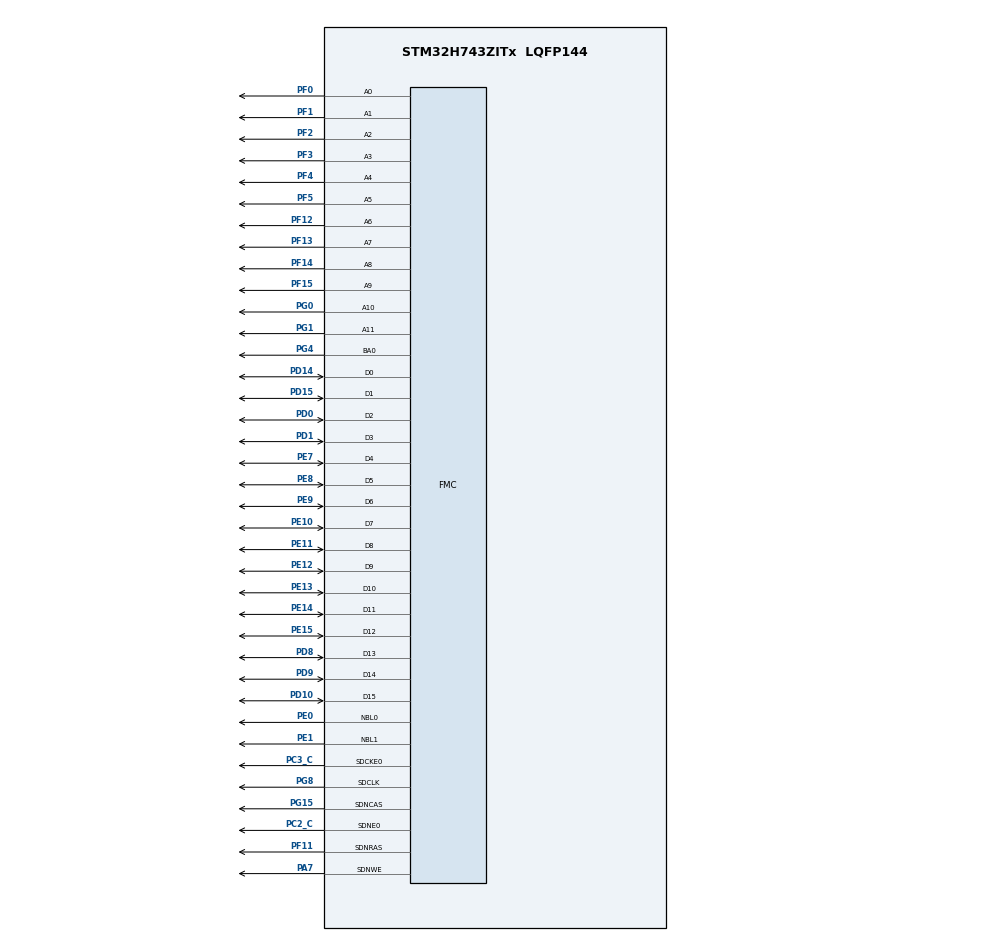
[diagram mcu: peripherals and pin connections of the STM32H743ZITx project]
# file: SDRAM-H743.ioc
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FMC.CASLatency1=FMC_SDRAM_CAS_LATENCY_2
FMC.ExitSelfRefreshDelay1=7
FMC.LoadToActiveDelay1=2
FMC.RCDDelay1=2
FMC.RPDelay1=2
FMC.ReadBurst1=FMC_SDRAM_RBURST_ENABLE
FMC.ReadPipeDelay1=FMC_SDRAM_RPIPE_DELAY_2
FMC.RowCycleDelay1=6
FMC.SDClockPeriod1=FMC_SDRAM_CLOCK_PERIOD_2
FMC.SelfRefreshTime1=6
FMC.WriteRecoveryTime1=4
Mcu.Family=STM32H7
Mcu.Name=STM32H743ZITx
Mcu.Package=LQFP144
NVIC.PriorityGroup=NVIC_PRIORITYGROUP_4
PA7.Signal=FMC_SDNWE
PC2_C.Mode=SdramChipSelect1_1
PC2_C.Signal=FMC_SDNE0
PC3_C.Mode=SdramChipSelect1_1
PC3_C.Signal=FMC_SDCKE0
PD0.Signal=FMC_D2_DA2
PD1.Signal=FMC_D3_DA3
PD10.Signal=FMC_D15_DA15
PD14.Signal=FMC_D0_DA0
PD15.Signal=FMC_D1_DA1
PD8.Signal=FMC_D13_DA13
PD9.Signal=FMC_D14_DA14
PE0.Signal=FMC_NBL0
PE1.Signal=FMC_NBL1
PE10.Signal=FMC_D7_DA7
PE11.Signal=FMC_D8_DA8
PE12.Signal=FMC_D9_DA9
PE13.Signal=FMC_D10_DA10
PE14.Signal=FMC_D11_DA11
PE15.Signal=FMC_D12_DA12
PE7.Signal=FMC_D4_DA4
PE8.Signal=FMC_D5_DA5
PE9.Signal=FMC_D6_DA6
PF0.Signal=FMC_A0
PF1.Signal=FMC_A1
PF11.Signal=FMC_SDNRAS
PF12.Signal=FMC_A6
PF13.Signal=FMC_A7
PF14.Signal=FMC_A8
PF15.Signal=FMC_A9
PF2.Signal=FMC_A2
PF3.Signal=FMC_A3
PF4.Signal=FMC_A4
PF5.Signal=FMC_A5
PG0.Signal=FMC_A10
PG1.Signal=FMC_A11
PG15.Signal=FMC_SDNCAS
PG4.Signal=FMC_A14_BA0
PG8.Signal=FMC_SDCLK
ProjectManager.HeapSize=0x200
ProjectManager.StackSize=0x400
ProjectManager.TargetToolchain=STM32CubeIDE
RCC.ADCFreq_Value=266000000
RCC.APB1Freq_Value=120000000
RCC.APB2Freq_Value=120000000
RCC.APB3Freq_Value=120000000
RCC.APB4Freq_Value=120000000
RCC.CortexFreq_Value=480000000
RCC.D1PPRE=RCC_APB3_DIV2
RCC.D2PPRE1=RCC_APB1_DIV2
RCC.D2PPRE2=RCC_APB2_DIV2
RCC.D3PPRE=RCC_APB4_DIV2
RCC.DIVM1=8
RCC.DIVM2=16
RCC.DIVN1=120
RCC.DIVN2=133
RCC.FMCCLockSelection=RCC_FMCCLKSOURCE_PLL2
RCC.HCLKFreq_Value=240000000
RCC.HPRE=RCC_HCLK_DIV2
RCC.HSE_VALUE=8000000
RCC.SYSCLKFreq_VALUE=480000000
RCC.SYSCLKSource=RCC_SYSCLKSOURCE_PLLCLK
RCC.USBFreq_Value=480000000
SH.FMC_A0.0=FMC_A0,12b-sda1
SH.FMC_A1.0=FMC_A1,12b-sda1
SH.FMC_A10.0=FMC_A10,12b-sda1
SH.FMC_A11.0=FMC_A11,12b-sda1
SH.FMC_A14_BA0.0=FMC_BA0,TwoSdramBanks1
SH.FMC_A2.0=FMC_A2,12b-sda1
SH.FMC_A3.0=FMC_A3,12b-sda1
SH.FMC_A4.0=FMC_A4,12b-sda1
SH.FMC_A5.0=FMC_A5,12b-sda1
SH.FMC_A6.0=FMC_A6,12b-sda1
SH.FMC_A7.0=FMC_A7,12b-sda1
SH.FMC_A8.0=FMC_A8,12b-sda1
SH.FMC_A9.0=FMC_A9,12b-sda1
SH.FMC_D0_DA0.0=FMC_D0,sd-16b-d1
SH.FMC_D10_DA10.0=FMC_D10,sd-16b-d1
SH.FMC_D11_DA11.0=FMC_D11,sd-16b-d1
SH.FMC_D12_DA12.0=FMC_D12,sd-16b-d1
SH.FMC_D13_DA13.0=FMC_D13,sd-16b-d1
SH.FMC_D14_DA14.0=FMC_D14,sd-16b-d1
SH.FMC_D15_DA15.0=FMC_D15,sd-16b-d1
SH.FMC_D1_DA1.0=FMC_D1,sd-16b-d1
SH.FMC_D2_DA2.0=FMC_D2,sd-16b-d1
SH.FMC_D3_DA3.0=FMC_D3,sd-16b-d1
SH.FMC_D4_DA4.0=FMC_D4,sd-16b-d1
SH.FMC_D5_DA5.0=FMC_D5,sd-16b-d1
SH.FMC_D6_DA6.0=FMC_D6,sd-16b-d1
SH.FMC_D7_DA7.0=FMC_D7,sd-16b-d1
SH.FMC_D8_DA8.0=FMC_D8,sd-16b-d1
SH.FMC_D9_DA9.0=FMC_D9,sd-16b-d1
SH.FMC_NBL0.0=FMC_NBL0,Sd2ByteEnable1
SH.FMC_NBL1.0=FMC_NBL1,Sd2ByteEnable1
SH.FMC_SDCLK.0=FMC_SDCLK,12b-sda1
SH.FMC_SDNCAS.0=FMC_SDNCAS,12b-sda1
SH.FMC_SDNRAS.0=FMC_SDNRAS,12b-sda1
SH.FMC_SDNWE.0=FMC_SDNWE,12b-sda1
board=custom

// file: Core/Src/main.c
/* USER CODE BEGIN Header */
/**
  ******************************************************************************
  * @file           : main.c
  * @brief          : Main program body
  ******************************************************************************
  * @attention
  *
  * Copyright (c) 2023 STMicroelectronics.
  * All rights reserved.
  *
  * This software is licensed under terms that can be found in the LICENSE file
  * in the root directory of this software component.
  * If no LICENSE file comes with this software, it is provided AS-IS.
  *
  ******************************************************************************
  */
/* USER CODE END Header */
#include "main.h"
#include "gpio.h"
#include "fmc.h"

void SystemClock_Config(void);

int main(void)
{

  /* MCU Configuration--------------------------------------------------------*/

  /* Reset of all peripherals, Initializes the Flash interface and the Systick. */
  HAL_Init();

  /* Configure the system clock */
  SystemClock_Config();

  /* Initialize all configured peripherals */
  MX_GPIO_Init();
  MX_FMC_Init();
  /* USER CODE BEGIN 2 */

  char str1[] = "Hello";
    char str2[] = "World";

    /* Copies contents of str2 to str1 */
    memcpy ((uint32_t *) 0xC0000000, str1, sizeof(str1));
    memcpy ((uint32_t *) 0xC0000000 + sizeof(str1), str2, sizeof(str2));

  /* USER CODE END 2 */

  /* Infinite loop */
  while (1)
  {

  }
}

void SystemClock_Config(void)
{
  RCC_OscInitTypeDef RCC_OscInitStruct = {0};
  RCC_ClkInitTypeDef RCC_ClkInitStruct = {0};

  /** Supply configuration update enable
  */
  HAL_PWREx_ConfigSupply(PWR_LDO_SUPPLY);

  /** Configure the main internal regulator output voltage
  */
  __HAL_PWR_VOLTAGESCALING_CONFIG(PWR_REGULATOR_VOLTAGE_SCALE1);

  while(!__HAL_PWR_GET_FLAG(PWR_FLAG_VOSRDY)) {}

  __HAL_RCC_SYSCFG_CLK_ENABLE();
  __HAL_PWR_VOLTAGESCALING_CONFIG(PWR_REGULATOR_VOLTAGE_SCALE0);

  while(!__HAL_PWR_GET_FLAG(PWR_FLAG_VOSRDY)) {}

  /** Macro to configure the PLL clock source
  */
  __HAL_RCC_PLL_PLLSOURCE_CONFIG(RCC_PLLSOURCE_HSI);

  /** Initializes the RCC Oscillators according to the specified parameters
  * in the RCC_OscInitTypeDef structure.
  */
  RCC_OscInitStruct.OscillatorType = RCC_OSCILLATORTYPE_HSI;
  RCC_OscInitStruct.HSIState = RCC_HSI_DIV1;
  RCC_OscInitStruct.HSICalibrationValue = RCC_HSICALIBRATION_DEFAULT;
  RCC_OscInitStruct.PLL.PLLState = RCC_PLL_ON;
  RCC_OscInitStruct.PLL.PLLSource = RCC_PLLSOURCE_HSI;
  RCC_OscInitStruct.PLL.PLLM = 8;
  RCC_OscInitStruct.PLL.PLLN = 120;
  RCC_OscInitStruct.PLL.PLLP = 2;
  RCC_OscInitStruct.PLL.PLLQ = 2;
  RCC_OscInitStruct.PLL.PLLR = 2;
  RCC_OscInitStruct.PLL.PLLRGE = RCC_PLL1VCIRANGE_3;
  RCC_OscInitStruct.PLL.PLLVCOSEL = RCC_PLL1VCOWIDE;
  RCC_OscInitStruct.PLL.PLLFRACN = 0;
  if (HAL_RCC_OscConfig(&RCC_OscInitStruct) != HAL_OK)
  {
    Error_Handler();
  }

  /** Initializes the CPU, AHB and APB buses clocks
  */
  RCC_ClkInitStruct.ClockType = RCC_CLOCKTYPE_HCLK|RCC_CLOCKTYPE_SYSCLK
                              |RCC_CLOCKTYPE_PCLK1|RCC_CLOCKTYPE_PCLK2
                              |RCC_CLOCKTYPE_D3PCLK1|RCC_CLOCKTYPE_D1PCLK1;
  RCC_ClkInitStruct.SYSCLKSource = RCC_SYSCLKSOURCE_PLLCLK;
  RCC_ClkInitStruct.SYSCLKDivider = RCC_SYSCLK_DIV1;
  RCC_ClkInitStruct.AHBCLKDivider = RCC_HCLK_DIV2;
  RCC_ClkInitStruct.APB3CLKDivider = RCC_APB3_DIV2;
  RCC_ClkInitStruct.APB1CLKDivider = RCC_APB1_DIV2;
  RCC_ClkInitStruct.APB2CLKDivider = RCC_APB2_DIV2;
  RCC_ClkInitStruct.APB4CLKDivider = RCC_APB4_DIV2;

  if (HAL_RCC_ClockConfig(&RCC_ClkInitStruct, FLASH_LATENCY_4) != HAL_OK)
  {
    Error_Handler();
  }
}

void Error_Handler(void)
{
  __disable_irq();
  while (1)
  {
  }
}
